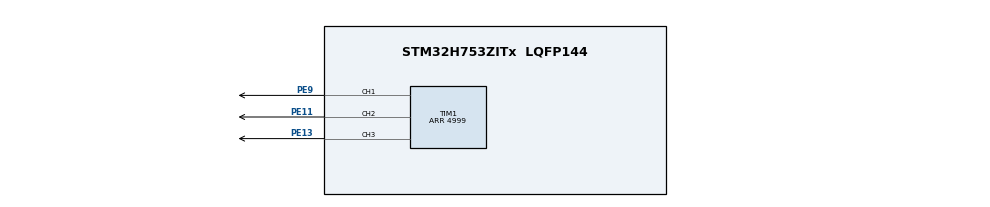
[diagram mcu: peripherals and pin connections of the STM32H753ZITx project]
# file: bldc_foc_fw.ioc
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CORTEX_M7.CPU_DCache=Disabled
CORTEX_M7.CPU_ICache=Disabled
CORTEX_M7.MPU_Control=__NULL
CORTEX_M7.default_mode_Activation=1
Mcu.Family=STM32H7
Mcu.Name=STM32H753ZITx
Mcu.Package=LQFP144
NUCLEO-H753ZI.BUTTON=1
NUCLEO-H753ZI.LD1=true
NUCLEO-H753ZI.LD2=true
NUCLEO-H753ZI.LD3=true
NUCLEO-H753ZI.VCP=true
NVIC.EXTI15_10_IRQn=true\:0\:0\:false\:false\:true\:false\:true\:true
NVIC.PriorityGroup=NVIC_PRIORITYGROUP_4
PC14-OSC32_IN\ (OSC32_IN).Signal=RCC_OSC32_IN
PC15-OSC32_OUT\ (OSC32_OUT).Signal=RCC_OSC32_OUT
PD8.Signal=USART3_TX
PD9.Signal=USART3_RX
PE11.Signal=S_TIM1_CH2
PE13.Signal=S_TIM1_CH3
PE9.Signal=S_TIM1_CH1
PH0-OSC_IN\ (PH0).Signal=RCC_OSC_IN
PH1-OSC_OUT\ (PH1).Signal=RCC_OSC_OUT
ProjectManager.HeapSize=0x200
ProjectManager.StackSize=0x400
ProjectManager.TargetToolchain=STM32CubeIDE
RCC.ADCFreq_Value=129000000
RCC.APB1Freq_Value=100000000
RCC.APB2Freq_Value=100000000
RCC.APB3Freq_Value=100000000
RCC.APB4Freq_Value=100000000
RCC.CortexFreq_Value=400000000
RCC.D1PPRE=RCC_APB3_DIV2
RCC.D2PPRE1=RCC_APB1_DIV2
RCC.D2PPRE2=RCC_APB2_DIV2
RCC.D3PPRE=RCC_APB4_DIV2
RCC.DIVM1=4
RCC.DIVN1=50
RCC.DIVQ1=4
RCC.HCLKFreq_Value=200000000
RCC.HPRE=RCC_HCLK_DIV2
RCC.HSE_VALUE=8000000
RCC.PLL2FRACN=0
RCC.PLL3FRACN=0
RCC.PLLFRACN=0
RCC.PWR_Regulator_Voltage_Scale=PWR_REGULATOR_VOLTAGE_SCALE1
RCC.SYSCLKFreq_VALUE=400000000
RCC.SYSCLKSource=RCC_SYSCLKSOURCE_PLLCLK
RCC.SupplySource=PWR_LDO_SUPPLY
RCC.USBFreq_Value=200000000
SH.S_TIM1_CH1.0=TIM1_CH1,PWM Generation1 CH1
SH.S_TIM1_CH2.0=TIM1_CH2,PWM Generation2 CH2
SH.S_TIM1_CH3.0=TIM1_CH3,PWM Generation3 CH3
TIM1.AutoReloadPreload=TIM_AUTORELOAD_PRELOAD_ENABLE
TIM1.Channel-PWM\ Generation1\ CH1=TIM_CHANNEL_1
TIM1.Channel-PWM\ Generation2\ CH2=TIM_CHANNEL_2
TIM1.Channel-PWM\ Generation3\ CH3=TIM_CHANNEL_3
TIM1.CounterMode=TIM_COUNTERMODE_CENTERALIGNED1
TIM1.Period=4999
VP_MEMORYMAP_VS_MEMORYMAP.Mode=CurAppReg
VP_NUCLEO-H753ZI_VS_BSP_COMMON.Mode=COMMON
VP_TIM1_VS_ClockSourceINT.Mode=Internal
board=NUCLEO-H753ZI

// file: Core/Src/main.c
/* USER CODE BEGIN Header */
/**
  ******************************************************************************
  * @file           : main.c
  * @brief          : Main program body
  ******************************************************************************
  * @attention
  *
  * Copyright (c) 2026 STMicroelectronics.
  * All rights reserved.
  *
  * This software is licensed under terms that can be found in the LICENSE file
  * in the root directory of this software component.
  * If no LICENSE file comes with this software, it is provided AS-IS.
  *
  ******************************************************************************
  */
/* USER CODE END Header */
#include "main.h"
#include "tim.h"
#include "gpio.h"

/* USER CODE BEGIN Includes */
/* Our three-phase PWM driver. */
#include "eg_pwm.h"
/* USER CODE END Includes */

COM_InitTypeDef BspCOMInit;

/* USER CODE BEGIN PV */
/* Boot line sent once at start-up; const keeps it in flash, not RAM. */
static const uint8_t eg_boot_msg[] = "BLDC FOC fw boot\r\n";
/* USER CODE END PV */

void SystemClock_Config(void);

int main(void)
{

  /* MCU Configuration--------------------------------------------------------*/

  /* Reset of all peripherals, Initializes the Flash interface and the Systick. */
  HAL_Init();

  /* Configure the system clock */
  SystemClock_Config();

  /* Initialize all configured peripherals */
  MX_GPIO_Init();
  MX_TIM1_Init();
  /* USER CODE BEGIN 2 */
  /* Start the three PWM channels at 0 % duty. Status ignored during bring-up. */
  (void)eg_pwm_init();
  /* Phase 0 at 25 %, phase 1 at 50 %, phase 2 at 75 % (values in permille). */
  (void)eg_pwm_set_duty_permille(0U, 250U);
  (void)eg_pwm_set_duty_permille(1U, 500U);
  (void)eg_pwm_set_duty_permille(2U, 750U);
  /* USER CODE END 2 */

  /* Initialize leds */
  BSP_LED_Init(LED_GREEN);
  BSP_LED_Init(LED_BLUE);
  BSP_LED_Init(LED_RED);

  /* Initialize USER push-button, will be used to trigger an interrupt each time it's pressed.*/
  BSP_PB_Init(BUTTON_USER, BUTTON_MODE_EXTI);

  /* Initialize COM1 port (115200, 8 bits (7-bit data + 1 stop bit), no parity */
  BspCOMInit.BaudRate   = 115200;
  BspCOMInit.WordLength = COM_WORDLENGTH_8B;
  BspCOMInit.StopBits   = COM_STOPBITS_1;
  BspCOMInit.Parity     = COM_PARITY_NONE;
  BspCOMInit.HwFlowCtl  = COM_HWCONTROL_NONE;
  if (BSP_COM_Init(COM1, &BspCOMInit) != BSP_ERROR_NONE)
  {
    Error_Handler();
  }

  /* Infinite loop */
  /* USER CODE BEGIN WHILE */
  /* BSP_COM_Init above has already set up USART3 (COM1) on the ST-Link virtual COM port,
    * so transmitting is safe from here on. hcom_uart[COM1] is the BSP-owned UART handle.
    * sizeof minus 1 drops the string's terminating zero; 100 ms is the timeout.
    * (void) cast: status is deliberately ignored during bring-up. */
   (void)HAL_UART_Transmit(&hcom_uart[COM1], eg_boot_msg, (uint16_t)(sizeof(eg_boot_msg) - 1UL), 100UL);
  while (1)
  {

    /* USER CODE END WHILE */

    /* USER CODE BEGIN 3 */
	  /* Toggle the green LED through the BSP so we can see the main loop is alive. */
	     BSP_LED_Toggle(LED_GREEN);
	     /* Wait 500 ms between toggles, which gives a 1 Hz blink. HAL_Delay relies on SysTick. */
	     HAL_Delay(500UL);
  }
  /* USER CODE END 3 */
}

void SystemClock_Config(void)
{
  RCC_OscInitTypeDef RCC_OscInitStruct = {0};
  RCC_ClkInitTypeDef RCC_ClkInitStruct = {0};

  /** Supply configuration update enable
  */
  HAL_PWREx_ConfigSupply(PWR_LDO_SUPPLY);

  /** Configure the main internal regulator output voltage
  */
  __HAL_PWR_VOLTAGESCALING_CONFIG(PWR_REGULATOR_VOLTAGE_SCALE1);

  while(!__HAL_PWR_GET_FLAG(PWR_FLAG_VOSRDY)) {}

  /** Initializes the RCC Oscillators according to the specified parameters
  * in the RCC_OscInitTypeDef structure.
  */
  RCC_OscInitStruct.OscillatorType = RCC_OSCILLATORTYPE_HSI;
  RCC_OscInitStruct.HSIState = RCC_HSI_DIV1;
  RCC_OscInitStruct.HSICalibrationValue = RCC_HSICALIBRATION_DEFAULT;
  RCC_OscInitStruct.PLL.PLLState = RCC_PLL_ON;
  RCC_OscInitStruct.PLL.PLLSource = RCC_PLLSOURCE_HSI;
  RCC_OscInitStruct.PLL.PLLM = 4;
  RCC_OscInitStruct.PLL.PLLN = 50;
  RCC_OscInitStruct.PLL.PLLP = 2;
  RCC_OscInitStruct.PLL.PLLQ = 4;
  RCC_OscInitStruct.PLL.PLLR = 2;
  RCC_OscInitStruct.PLL.PLLRGE = RCC_PLL1VCIRANGE_3;
  RCC_OscInitStruct.PLL.PLLVCOSEL = RCC_PLL1VCOWIDE;
  RCC_OscInitStruct.PLL.PLLFRACN = 0;
  if (HAL_RCC_OscConfig(&RCC_OscInitStruct) != HAL_OK)
  {
    Error_Handler();
  }

  /** Initializes the CPU, AHB and APB buses clocks
  */
  RCC_ClkInitStruct.ClockType = RCC_CLOCKTYPE_HCLK|RCC_CLOCKTYPE_SYSCLK
                              |RCC_CLOCKTYPE_PCLK1|RCC_CLOCKTYPE_PCLK2
                              |RCC_CLOCKTYPE_D3PCLK1|RCC_CLOCKTYPE_D1PCLK1;
  RCC_ClkInitStruct.SYSCLKSource = RCC_SYSCLKSOURCE_PLLCLK;
  RCC_ClkInitStruct.SYSCLKDivider = RCC_SYSCLK_DIV1;
  RCC_ClkInitStruct.AHBCLKDivider = RCC_HCLK_DIV2;
  RCC_ClkInitStruct.APB3CLKDivider = RCC_APB3_DIV2;
  RCC_ClkInitStruct.APB1CLKDivider = RCC_APB1_DIV2;
  RCC_ClkInitStruct.APB2CLKDivider = RCC_APB2_DIV2;
  RCC_ClkInitStruct.APB4CLKDivider = RCC_APB4_DIV2;

  if (HAL_RCC_ClockConfig(&RCC_ClkInitStruct, FLASH_LATENCY_2) != HAL_OK)
  {
    Error_Handler();
  }
}

void Error_Handler(void)
{
  __disable_irq();
  while (1)
  {
  }
}
